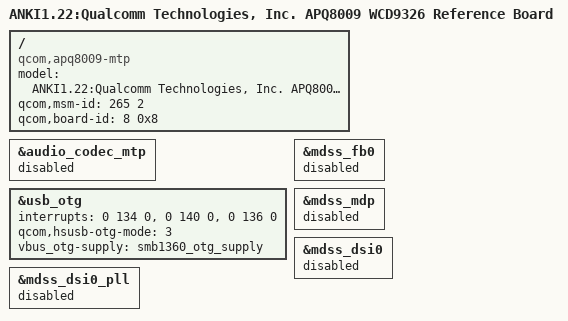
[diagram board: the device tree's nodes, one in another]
/*
 * Copyright (c) 2016-2017, The Linux Foundation. All rights reserved.
 *
 * This program is free software; you can redistribute it and/or modify
 * it under the terms of the GNU General Public License version 2 and
 * only version 2 as published by the Free Software Foundation.
 *
 * This program is distributed in the hope that it will be useful,
 * but WITHOUT ANY WARRANTY; without even the implied warranty of
 * MERCHANTABILITY or FITNESS FOR A PARTICULAR PURPOSE.  See the
 * GNU General Public License for more details.
 */

/dts-v1/;

#include "msm8909-mtp.dtsi"
#include "msm8909-pm8916.dtsi"
#include "msm8909-pm8916-mtp.dtsi"
#include "apq8009-memory.dtsi"

/ {
	model = "ANKI1.22:Qualcomm Technologies, Inc. APQ8009 WCD9326 Reference Board";
	compatible = "qcom,apq8009-mtp", "qcom,apq8009", "qcom,mtp";
	qcom,msm-id = <265 2>;
	qcom,board-id= <8 0x8>;
};

&audio_codec_mtp {
	status = "disabled";
};

&usb_otg {
	interrupts = <0 134 0>,<0 140 0>,<0 136 0>;
	interrupt-names = "core_irq", "async_irq", "phy_irq";

	qcom,hsusb-otg-mode = <3>;
	vbus_otg-supply = <&smb1360_otg_supply>;
};

&mdss_fb0 {
	status = "disabled";
	/delete-node/ qcom,cont-splash-memory;
};

&mdss_mdp {
	status = "disabled";
};

&mdss_dsi0_pll {
	status = "disabled";
};

&mdss_dsi0 {
	status = "disabled";
};

/delete-node/ &cont_splash_mem;
